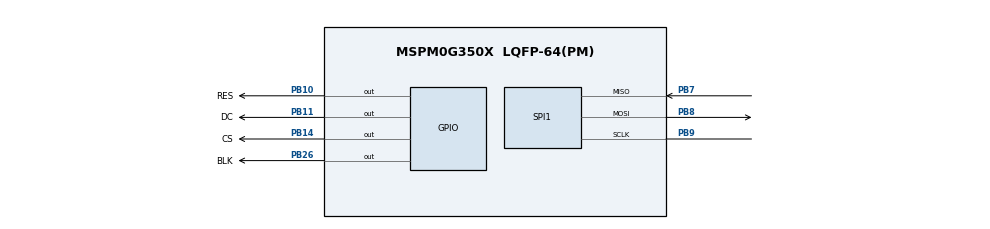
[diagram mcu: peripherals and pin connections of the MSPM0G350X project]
/**
 * @cliArgs --device "MSPM0G350X" --part "Default" --package "LQFP-64(PM)" --product "mspm0_sdk@2.02.00.05"
 * @versions {"tool":"1.21.1+3772"}
 */

/**
 * Import the modules used in this configuration.
 */
const GPIO    = scripting.addModule("/ti/driverlib/GPIO", {}, false);
const GPIO1   = GPIO.addInstance();
const GPIO2   = GPIO.addInstance();
const SPI     = scripting.addModule("/ti/driverlib/SPI", {}, false);
const SPI1    = SPI.addInstance();
const SYSCTL  = scripting.addModule("/ti/driverlib/SYSCTL");
const SYSTICK = scripting.addModule("/ti/driverlib/SYSTICK");
const TIMER   = scripting.addModule("/ti/driverlib/TIMER", {}, false);
const TIMER1  = TIMER.addInstance();

/**
 * Write custom configuration values to the imported modules.
 */
const divider6       = system.clockTree["PLL_CLK2X_DIV"];
divider6.divideValue = 4;

const divider7       = system.clockTree["PLL_PDIV"];
divider7.divideValue = 2;

const divider9       = system.clockTree["UDIV"];
divider9.divideValue = 2;

const gate7  = system.clockTree["MFCLKGATE"];
gate7.enable = true;

const multiplier2         = system.clockTree["PLL_QDIV"];
multiplier2.multiplyValue = 10;

const mux8       = system.clockTree["HSCLKMUX"];
mux8.inputSelect = "HSCLKMUX_SYSPLL2X";

GPIO1.$name                          = "I2C";
GPIO1.associatedPins.create(2);
GPIO1.associatedPins[0].assignedPort = "PORTA";
GPIO1.associatedPins[0].initialValue = "SET";
GPIO1.associatedPins[0].ioStructure  = "OD";
GPIO1.associatedPins[0].assignedPin  = "0";
GPIO1.associatedPins[0].$name        = "SDA";
GPIO1.associatedPins[1].initialValue = "SET";
GPIO1.associatedPins[1].ioStructure  = "OD";
GPIO1.associatedPins[1].assignedPort = "PORTA";
GPIO1.associatedPins[1].assignedPin  = "1";
GPIO1.associatedPins[1].$name        = "SCL";

const Board = scripting.addModule("/ti/driverlib/Board", {}, false);

GPIO2.$name                          = "LCD";
GPIO2.associatedPins.create(4);
GPIO2.associatedPins[0].$name        = "RES";
GPIO2.associatedPins[0].ioStructure  = "SD";
GPIO2.associatedPins[0].assignedPort = "PORTB";
GPIO2.associatedPins[0].assignedPin  = "10";
GPIO2.associatedPins[0].pin.$assign  = "PB10";
GPIO2.associatedPins[1].$name        = "DC";
GPIO2.associatedPins[1].ioStructure  = "SD";
GPIO2.associatedPins[1].assignedPort = "PORTB";
GPIO2.associatedPins[1].assignedPin  = "11";
GPIO2.associatedPins[1].pin.$assign  = "PB11";
GPIO2.associatedPins[2].$name        = "CS";
GPIO2.associatedPins[2].ioStructure  = "SD";
GPIO2.associatedPins[2].assignedPort = "PORTB";
GPIO2.associatedPins[2].assignedPin  = "14";
GPIO2.associatedPins[2].pin.$assign  = "PB14";
GPIO2.associatedPins[3].$name        = "BLK";
GPIO2.associatedPins[3].ioStructure  = "SD";
GPIO2.associatedPins[3].assignedPort = "PORTB";
GPIO2.associatedPins[3].assignedPin  = "26";
GPIO2.associatedPins[3].pin.$assign  = "PB26";

SPI1.frameFormat                        = "MOTO3";
SPI1.$name                              = "SPI_LCD";
SPI1.peripheral.$assign                 = "SPI1";
SPI1.peripheral.sclkPin.$assign         = "PB9";
SPI1.peripheral.mosiPin.$assign         = "PB8";
SPI1.peripheral.misoPin.$assign         = "PB7";
SPI1.sclkPinConfig.$name                = "ti_driverlib_gpio_GPIOPinGeneric0";
SPI1.sclkPinConfig.direction            = scripting.forceWrite("OUTPUT");
SPI1.sclkPinConfig.onlyInternalResistor = scripting.forceWrite(false);
SPI1.sclkPinConfig.passedPeripheralType = scripting.forceWrite("Digital");
SPI1.mosiPinConfig.$name                = "ti_driverlib_gpio_GPIOPinGeneric1";
SPI1.mosiPinConfig.direction            = scripting.forceWrite("OUTPUT");
SPI1.mosiPinConfig.hideOutputInversion  = scripting.forceWrite(false);
SPI1.mosiPinConfig.onlyInternalResistor = scripting.forceWrite(false);
SPI1.mosiPinConfig.passedPeripheralType = scripting.forceWrite("Digital");
SPI1.misoPinConfig.$name                = "ti_driverlib_gpio_GPIOPinGeneric2";
SPI1.misoPinConfig.onlyInternalResistor = scripting.forceWrite(false);
SPI1.misoPinConfig.passedPeripheralType = scripting.forceWrite("Digital");

SYSCTL.forceDefaultClkConfig = true;
SYSCTL.clockTreeEn           = true;

SYSTICK.periodEnable    = true;
SYSTICK.interruptEnable = true;
SYSTICK.systickEnable   = true;
SYSTICK.period          = 80000;

TIMER1.$name              = "TIMER_0";
TIMER1.timerMode          = "PERIODIC";
TIMER1.timerPeriod        = "5 ms";
TIMER1.timerStartTimer    = true;
TIMER1.interrupts         = ["ZERO"];
TIMER1.timerClkPrescale   = 100;
TIMER1.peripheral.$assign = "TIMG0";

/**
 * Pinmux solution for unlocked pins/peripherals. This ensures that minor changes to the automatic solver in a future
 * version of the tool will not impact the pinmux you originally saw.  These lines can be completely deleted in order to
 * re-solve from scratch.
 */
GPIO1.associatedPins[0].pin.$suggestSolution = "PA0";
GPIO1.associatedPins[1].pin.$suggestSolution = "PA1";
Board.peripheral.$suggestSolution            = "DEBUGSS";
Board.peripheral.swclkPin.$suggestSolution   = "PA20";
Board.peripheral.swdioPin.$suggestSolution   = "PA19";
